# iorx74m register map
Registers from a debugger description file.
Registers are 32-bit, access not given, no defined reset value unless marked. A register's access mark holds for its fields unless they carry their own. Addresses are absolute; registers are grouped by the start of their names; lines under a group give offsets from that group; [hi:lo] are bit positions; {n}, {i} and the like mark numbered series; 'fields as' and 'values as' point back to an identical list; <NAME> marks a mode.

## BUS
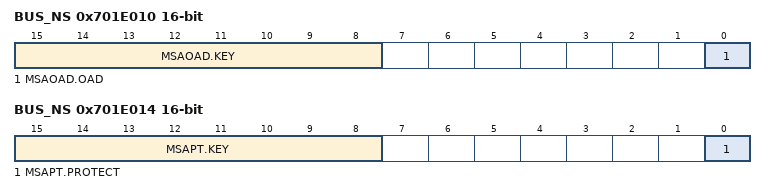
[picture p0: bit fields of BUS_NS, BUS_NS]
0x701E010 BUS_NS 16-bit
  [15:8] MSAOAD.KEY, [0] MSAOAD.OAD
0x701E014 BUS_NS 16-bit
  [15:8] MSAPT.KEY, [0] MSAPT.PROTECT

## CPU
0x1000004 CPU_CTRL_NS
  [0] CPULOCKCRNS.LCKNSMPU
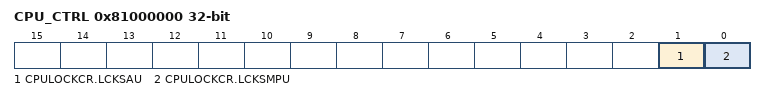
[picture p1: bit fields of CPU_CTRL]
0x81000000 CPU_CTRL
  [1] CPULOCKCR.LCKSAU, [0] CPULOCKCR.LCKSMPU

## DTC0
0x7007C00 DTC0_NS 8-bit
  [4] DTCCR.RRS
0x7007C04 DTC0_NS
  [31:0] DTCVBR.DTCVBR

## ELC
0x7801000 ELC_NS 8-bit
  [7] ELCR.ELCON
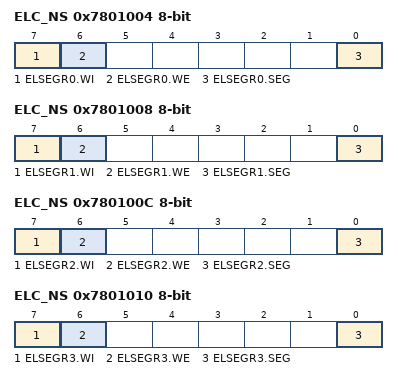
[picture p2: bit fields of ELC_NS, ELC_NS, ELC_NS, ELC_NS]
0x7801004 ELC_NS 8-bit
  [7] ELSEGR0.WI, [6] ELSEGR0.WE, [0] ELSEGR0.SEG
0x7801008 ELC_NS 8-bit
  [7] ELSEGR1.WI, [6] ELSEGR1.WE, [0] ELSEGR1.SEG
0x780100C ELC_NS 8-bit
  [7] ELSEGR2.WI, [6] ELSEGR2.WE, [0] ELSEGR2.SEG
0x7801010 ELC_NS 8-bit
  [7] ELSEGR3.WI, [6] ELSEGR3.WE, [0] ELSEGR3.SEG
0x7801090 ELC_NS 8-bit
  [3:2] ELOPA.CMT1MD
0x7801094 ELC_NS 8-bit
  [1:0] ELOPB.CMTW0MD
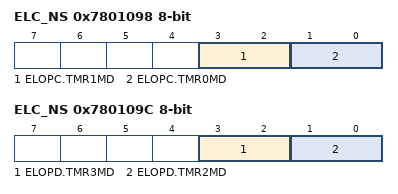
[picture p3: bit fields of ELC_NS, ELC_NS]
0x7801098 ELC_NS 8-bit
  [3:2] ELOPC.TMR1MD, [1:0] ELOPC.TMR0MD
0x780109C ELC_NS 8-bit
  [3:2] ELOPD.TMR3MD, [1:0] ELOPD.TMR2MD
0x7801100 ELC_NS 16-bit
  [9:0] ELSR0.ELS
0x7801104 ELC_NS 16-bit
  [9:0] ELSR1.ELS
0x7801108 ELC_NS 16-bit
  [9:0] ELSR2.ELS
0x780110C ELC_NS 16-bit
  [9:0] ELSR3.ELS
0x7801110 ELC_NS 16-bit
  [9:0] ELSR4.ELS
0x7801114 ELC_NS 16-bit
  [9:0] ELSR5.ELS
0x7801118 ELC_NS 16-bit
  [9:0] ELSR6.ELS
0x780111C ELC_NS 16-bit
  [9:0] ELSR7.ELS
0x7801120 ELC_NS 16-bit
  [9:0] ELSR8.ELS
0x7801124 ELC_NS 16-bit
  [9:0] ELSR9.ELS
0x7801128 ELC_NS 16-bit
  [9:0] ELSR10.ELS
0x780112C ELC_NS 16-bit
  [9:0] ELSR11.ELS
0x7801130 ELC_NS 16-bit
  [9:0] ELSR12.ELS
0x7801134 ELC_NS 16-bit
  [9:0] ELSR13.ELS
0x7801138 ELC_NS 16-bit
  [9:0] ELSR14.ELS
0x780113C ELC_NS 16-bit
  [9:0] ELSR15.ELS
0x7801140 ELC_NS 16-bit
  [9:0] ELSR16.ELS
0x7801144 ELC_NS 16-bit
  [9:0] ELSR17.ELS
0x7801148 ELC_NS 16-bit
  [9:0] ELSR18.ELS
0x780114C ELC_NS 16-bit
  [9:0] ELSR19.ELS
0x7801150 ELC_NS 16-bit
  [9:0] ELSR20.ELS
0x7801154 ELC_NS 16-bit
  [9:0] ELSR21.ELS
0x7801158 ELC_NS 16-bit
  [9:0] ELSR22.ELS
0x780115C ELC_NS 16-bit
  [9:0] ELSR23.ELS
0x7801160 ELC_NS 16-bit
  [9:0] ELSR24.ELS
0x7801164 ELC_NS 16-bit
  [9:0] ELSR25.ELS
0x7801168 ELC_NS 16-bit
  [9:0] ELSR26.ELS
0x78011B8 ELC_NS 16-bit
  [9:0] ELSR46.ELS
0x78011BC ELC_NS 16-bit
  [9:0] ELSR47.ELS
0x78011C8 ELC_NS 16-bit
  [9:0] ELSR50.ELS
0x78011CC ELC_NS 16-bit
  [9:0] ELSR51.ELS
0x78011D0 ELC_NS 16-bit
  [9:0] ELSR52.ELS
0x78011D4 ELC_NS 16-bit
  [9:0] ELSR53.ELS
0x78011D8 ELC_NS 16-bit
  [9:0] ELSR54.ELS
0x78011DC ELC_NS 16-bit
  [9:0] ELSR55.ELS
0x78011E0 ELC_NS 16-bit
  [9:0] ELSR56.ELS
0x78011E4 ELC_NS 16-bit
  [9:0] ELSR57.ELS
0x78011E8 ELC_NS 16-bit
  [9:0] ELSR58.ELS
0x78011EC ELC_NS 16-bit
  [9:0] ELSR59.ELS
0x78011F0 ELC_NS 16-bit
  [9:0] ELSR60.ELS
0x78011F4 ELC_NS 16-bit
  [9:0] ELSR61.ELS
0x78011F8 ELC_NS 16-bit
  [9:0] ELSR62.ELS
0x78011FC ELC_NS 16-bit
  [9:0] ELSR63.ELS
0x7801200 ELC_NS 16-bit
  [9:0] ELSR64.ELS
0x7801204 ELC_NS 16-bit
  [9:0] ELSR65.ELS
0x7801208 ELC_NS 16-bit
  [9:0] ELSR66.ELS
0x780120C ELC_NS 16-bit
  [9:0] ELSR67.ELS
0x7801210 ELC_NS 16-bit
  [9:0] ELSR68.ELS
0x7801214 ELC_NS 16-bit
  [9:0] ELSR69.ELS
0x7801218 ELC_NS 16-bit
  [9:0] ELSR70.ELS
0x780121C ELC_NS 16-bit
  [9:0] ELSR71.ELS
0x7801220 ELC_NS 16-bit
  [9:0] ELSR72.ELS
0x7801224 ELC_NS 16-bit
  [9:0] ELSR73.ELS
0x7801228 ELC_NS 16-bit
  [9:0] ELSR74.ELS
0x780122C ELC_NS 16-bit
  [9:0] ELSR75.ELS
0x7801230 ELC_NS 16-bit
  [9:0] ELSR76.ELS
0x7801234 ELC_NS 16-bit
  [9:0] ELSR77.ELS
0x7801238 ELC_NS 16-bit
  [9:0] ELSR78.ELS
0x7801260 ELC_NS 16-bit
  [9:0] ELSR88.ELS
0x7801264 ELC_NS 16-bit
  [9:0] ELSR89.ELS
0x7801268 ELC_NS 16-bit
  [9:0] ELSR90.ELS
0x780126C ELC_NS 16-bit
  [9:0] ELSR91.ELS
